VERSION ""

NS_ :

BS_:

BU_: AEB
VAL_TABLE_ vt_TMSPumpControlMode 21 "NA" 2 "ParkMode" 1 "ChargeMode" 0 "DriveMode" ;
VAL_TABLE_ vtHVHeaterTempSP 3 "NA" 2 "TempSP2" 1 "TempSP1" 0 "NA1" ;
VAL_TABLE_ ChargeFaultState 4 "NEVER_ENABLE" 3 "FAULT_DELAY_BEFORE_EN" 2 "IGN_DISABLE" 1 "FAULT_DELAY_BEFORE_DIS" 0 "NO_FAULT" ;
VAL_TABLE_ ChargeOverride 3 "ChargingFault" 2 "ChargeAcOverrideEn" 1 "ChargeChademoOverrideEn" 0 "ChargeOverrideDis" ;
VAL_TABLE_ LvOverideStatus 3 "LvOverrideEn" 2 "LvOverrideEn_5minWait" 1 "LvThrCheckHVSock" 0 "LvOverideDis" ;
VAL_TABLE_ HVHeterPWMCMD_t 15 "NA" 13 "STANDBY1" 12 "OVERHEAT_UNLOCK" 11 "P8" 10 "P7" 9 "P6" 8 "P5" 7 "P4" 6 "P3" 5 "P2" 4 "P1" 3 "TEMP_SP2" 2 "TEMP_SP1" 1 "STANDBY" 0 "OFF" ;
VAL_TABLE_ HVHeaterPWMSTAT_t 15 "NA" 13 "LOCKED_PERM" 12 "LOCKED_OVERHEAT" 11 "LOCKED_TEMPOR" 10 "Ta75_PaSP" 9 "Tb75_PaSP" 8 "Tb40_PaSP" 7 "Tb0_PaSP" 6 "Ta75_PbSP" 5 "Tb75_PbSP" 4 "Tb40_PbSP" 3 "Tb0_PbSP" 2 "SP2" 1 "SP1" 0 "OFF" ;
VAL_TABLE_ HVDrStat_t 11 "ERRCHANGESP" 10 "HV_POWER_PROBLEM" 15 "NA" 9 "ERROR" 8 "FLOWNOTREADY" 7 "LOCKED_PERM" 6 "LOCKED_OVERHEAT" 5 "LOCKED_TEMPOR" 4 "SP_Request" 3 "SP_above" 2 "SP_below" 1 "STANDBY" 0 "OFF" ;
VAL_TABLE_ CabinBlowDirectionTbl 7 "NA" 0 "Reserved" 4 "Take_no_Action" 3 "Down" 2 "Med" 1 "Up" ;
VAL_TABLE_ vAction_t 3 "va_Take_no_action" 2 "va_Reserved" 1 "va_On" 0 "va_Off" ;
VAL_TABLE_ vtEnergyMode 7 "Not Available" 1 "RangeExtender" 0 "PureElectric" ;
VAL_TABLE_ vtOnOff 3 "Not available" 2 "Error" 1 "On" 0 "Off" ;

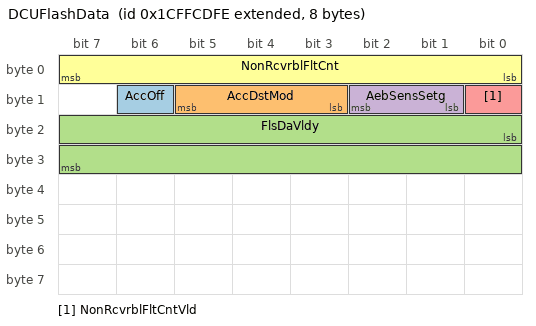
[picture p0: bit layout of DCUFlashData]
BO_ 2634010110 DCUFlashData: 8 AEB
 SG_ AccOff : 14|1@1+ (1,0) [0|1] "" Vector__XXX
 SG_ AccDstMod : 11|3@1+ (1,0) [0|7] "" Vector__XXX
 SG_ FlsDaVldy : 16|16@1+ (1,0) [0|65535] "" Vector__XXX
 SG_ AebSensSetg : 9|2@1+ (1,0) [0|3] "" Vector__XXX
 SG_ NonRcvrblFltCntVld : 8|1@1+ (1,0) [0|1] "" Vector__XXX
 SG_ NonRcvrblFltCnt : 0|8@1+ (1,0) [0|255] "" Vector__XXX

CM_ SG_ 2634010110 AccOff "ACC Off setting";
CM_ SG_ 2634010110 AccDstMod "ACC Distance mode";
CM_ SG_ 2634010110 FlsDaVldy "Flash Data validity check value";
CM_ SG_ 2634010110 AebSensSetg "AEB sensitivity setting";
CM_ SG_ 2634010110 NonRcvrblFltCntVld "Non recoverable fault counter valid flag";
CM_ SG_ 2634010110 NonRcvrblFltCnt "Non recoverable fault counter";
BA_DEF_  "DBName" STRING ;
BA_DEF_ SG_  "SigType" ENUM  "Default","Range","RangeSigned","ASCII","Discrete","Control","ReferencePGN","DTC","StringDelimiter","StringLength","StringLengthControl","MessageCounter","MessageChecksum";
BA_DEF_ SG_  "GenSigSendType" ENUM  "Cyclic","OnWrite","OnWriteWithRepetition","OnChange","OnChangeWithRepetition","IfActive","IfActiveWithRepetition","NoSigSendType";
BA_DEF_ SG_  "GenSigILSupport" ENUM  "No","Yes";
BA_DEF_ SG_  "GenSigEVName" STRING ;
BA_DEF_ BO_  "GenMsgILSupport" ENUM  "No","Yes";
BA_DEF_ BO_  "GenMsgRequestable" INT 0 1;
BA_DEF_ BO_  "GenMsgSendType" ENUM  "cyclic","NotUsed","NotUsed","NotUsed","NotUsed","NotUsed","NotUsed","IfActive","noMsgSendType";
BA_DEF_ BO_  "VFrameFormat" ENUM  "StandardCAN","ExtendedCAN","reserved","J1939PG";
BA_DEF_ BU_  "NmStationAddress" INT 0 255;
BA_DEF_  "SAE_J1939_DA_SpecVersion" STRING ;
BA_DEF_  "SAE_J1939_81_SpecVersion" STRING ;
BA_DEF_  "DatabaseVersion" STRING ;
BA_DEF_  "BusType" STRING ;
BA_DEF_  "ProtocolType" STRING ;
BA_DEF_  "SAE_J1939_75_SpecVersion" STRING ;
BA_DEF_  "SAE_J1939_21_SpecVersion" STRING ;
BA_DEF_  "SAE_J1939_73_SpecVersion" STRING ;
BA_DEF_  "SAE_J1939_71_SpecVersion" STRING ;
BA_DEF_DEF_  "DBName" "";
BA_DEF_DEF_  "SigType" "Default";
BA_DEF_DEF_  "GenSigSendType" "NoSigSendType";
BA_DEF_DEF_  "GenSigILSupport" "Yes";
BA_DEF_DEF_  "GenSigEVName" "Env@Nodename_@Signame";
BA_DEF_DEF_  "GenMsgILSupport" "Yes";
BA_DEF_DEF_  "GenMsgRequestable" 1;
BA_DEF_DEF_  "GenMsgSendType" "noMsgSendType";
BA_DEF_DEF_  "VFrameFormat" "J1939PG";
BA_DEF_DEF_  "NmStationAddress" 254;
BA_DEF_DEF_  "SAE_J1939_DA_SpecVersion" "";
BA_DEF_DEF_  "SAE_J1939_81_SpecVersion" "";
BA_DEF_DEF_  "DatabaseVersion" "";
BA_DEF_DEF_  "BusType" "";
BA_DEF_DEF_  "ProtocolType" "";
BA_DEF_DEF_  "SAE_J1939_75_SpecVersion" "";
BA_DEF_DEF_  "SAE_J1939_21_SpecVersion" "";
BA_DEF_DEF_  "SAE_J1939_73_SpecVersion" "";
BA_DEF_DEF_  "SAE_J1939_71_SpecVersion" "";
BA_ "SAE_J1939_71_SpecVersion" "2012-10";
BA_ "SAE_J1939_73_SpecVersion" "2012-10";
BA_ "SAE_J1939_21_SpecVersion" "2006-10";
BA_ "SAE_J1939_75_SpecVersion" "2012-05";
BA_ "ProtocolType" "J1939";
BA_ "BusType" "CAN";
BA_ "DatabaseVersion" "8.5";
BA_ "SAE_J1939_81_SpecVersion" "2012-05";
BA_ "SAE_J1939_DA_SpecVersion" "2015-01";
BA_ "DBName" "AEB_FlashData";
BA_ "NmStationAddress" BU_ AEB 0;
